# STM32H7x7_CM7 register map
File version: 1.0
CPU: CM7 r0p1, little endian, MPU, FPU, 4 interrupt priority bits
Registers are 32-bit, read-write, reset 0x0 unless marked. A register's access mark holds for its fields unless they carry their own. Offsets are from the block's base; [hi:lo] are bit positions.

## CAN_CCU — CCU registers
Base 0x4000A800
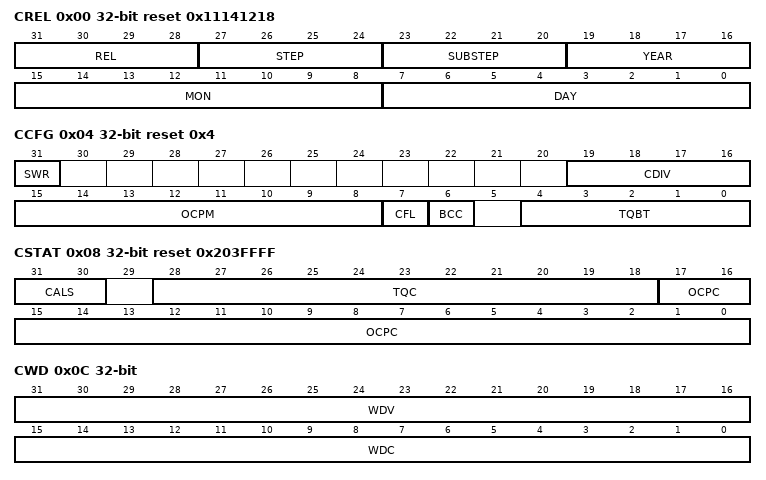
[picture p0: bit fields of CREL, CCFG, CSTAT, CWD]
0x00 CREL ro reset 0x11141218 — Clock Calibration Unit Core Release Register
  [31:28] REL — Core Release
  [27:24] STEP — Step of Core Release
  [23:20] SUBSTEP — Sub-step of Core Release
  [19:16] YEAR — Time Stamp Year
  [15:8] MON — Time Stamp Month
  [7:0] DAY — Time Stamp Day
0x04 CCFG reset 0x4 — Calibration Configuration Register
  [31] SWR — Software Reset
  [19:16] CDIV — Clock Divider
  [15:8] OCPM — Oscillator Clock Periods Minimum
  [7] CFL — Calibration Field Length
  [6] BCC — Bypass Clock Calibration
  [4:0] TQBT — Time Quanta per Bit Time
0x08 CSTAT ro reset 0x203FFFF — Calibration Status Register
  [31:30] CALS — Calibration State
  [28:18] TQC — Time Quanta Counter
  [17:0] OCPC — Oscillator Clock Period Counter
0x0C CWD access per field — Calibration Watchdog Register
  [31:16] WDV ro, [15:0] WDC rw
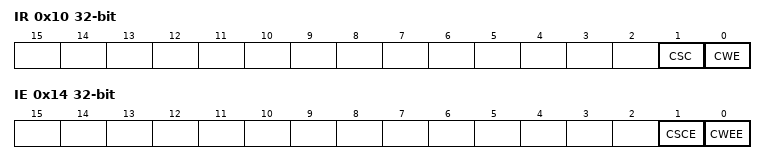
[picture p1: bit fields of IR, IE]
0x10 IR — Clock Calibration Unit Interrupt Register
  [1] CSC — Calibration State Changed
  [0] CWE — Calibration Watchdog Event
0x14 IE — Clock Calibration Unit Interrupt Enable Register
  [1] CSCE — Calibration State Changed Enable
  [0] CWEE — Calibration Watchdog Event Enable

## TIM16 — General-purpose-timers
Base 0x40014400
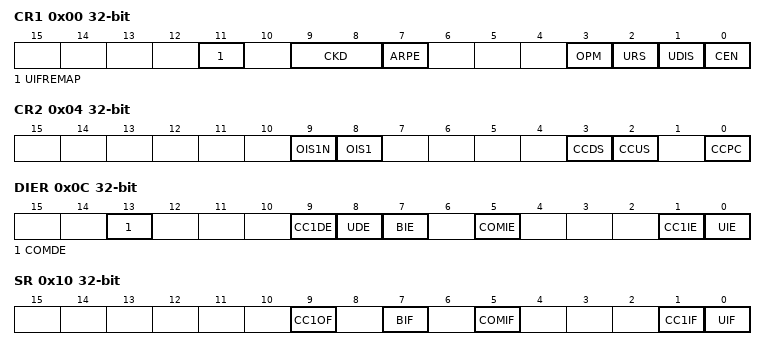
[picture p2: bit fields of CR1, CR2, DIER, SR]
0x00 CR1 — control register 1
  [11] UIFREMAP — UIF status bit remapping
  [9:8] CKD — Clock division
  [7] ARPE — Auto-reload preload enable
  [3] OPM — One-pulse mode
  [2] URS — Update request source
  [1] UDIS — Update disable
  [0] CEN — Counter enable
0x04 CR2 — control register 2
  [9] OIS1N — Output Idle state 1
  [8] OIS1 — Output Idle state 1
  [3] CCDS — Capture/compare DMA selection
  [2] CCUS — Capture/compare control update selection
  [0] CCPC — Capture/compare preloaded control
0x0C DIER — DMA/Interrupt enable register
  [13] COMDE — COM DMA request enable
  [9] CC1DE — Capture/Compare 1 DMA request enable
  [8] UDE — Update DMA request enable
  [7] BIE — Break interrupt enable
  [5] COMIE — COM interrupt enable
  [1] CC1IE — Capture/Compare 1 interrupt enable
  [0] UIE — Update interrupt enable
0x10 SR — status register
  [9] CC1OF — Capture/Compare 1 overcapture flag
  [7] BIF — Break interrupt flag
  [5] COMIF — COM interrupt flag
  [1] CC1IF — Capture/compare 1 interrupt flag
  [0] UIF — Update interrupt flag
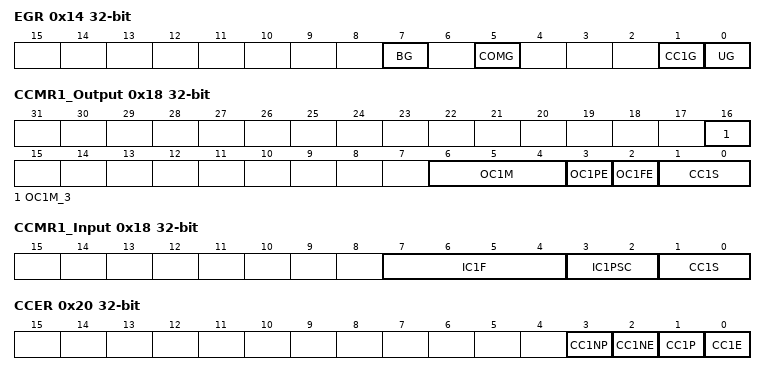
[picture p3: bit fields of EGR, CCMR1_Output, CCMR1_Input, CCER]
0x14 EGR wo — event generation register
  [7] BG — Break generation
  [5] COMG — Capture/Compare control update generation
  [1] CC1G — Capture/compare 1 generation
  [0] UG — Update generation
0x18 CCMR1_Output — capture/compare mode register (output mode)
  [16] OC1M_3 — Output Compare 1 mode
  [6:4] OC1M — Output Compare 1 mode
  [3] OC1PE — Output Compare 1 preload enable
  [2] OC1FE — Output Compare 1 fast enable
  [1:0] CC1S — Capture/Compare 1 selection
0x18 CCMR1_Input (alternate view of CCMR1_Output) — capture/compare mode register 1 (input mode)
  [7:4] IC1F — Input capture 1 filter
  [3:2] IC1PSC — Input capture 1 prescaler
  [1:0] CC1S — Capture/Compare 1 selection
0x20 CCER — capture/compare enable register
  [3] CC1NP — Capture/Compare 1 output Polarity
  [2] CC1NE — Capture/Compare 1 complementary output enable
  [1] CC1P — Capture/Compare 1 output Polarity
  [0] CC1E — Capture/Compare 1 output enable
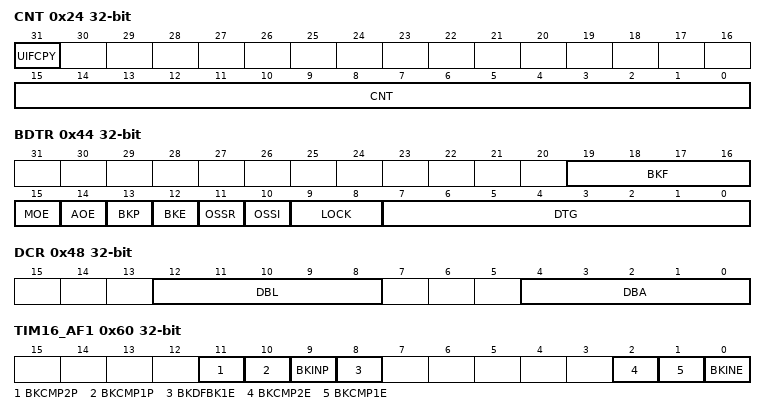
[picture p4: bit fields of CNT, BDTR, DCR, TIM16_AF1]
0x24 CNT access per field — counter
  [31] UIFCPY ro — UIF Copy
  [15:0] CNT rw — counter value
0x28 PSC — prescaler
  [15:0] PSC — Prescaler value
0x2C ARR — auto-reload register
  [15:0] ARR — Auto-reload value
0x30 RCR — repetition counter register
  [7:0] REP — Repetition counter value
0x34 CCR1 — capture/compare register 1
  [15:0] CCR1 — Capture/Compare 1 value
0x44 BDTR — break and dead-time register
  [19:16] BKF — Break filter
  [15] MOE — Main output enable
  [14] AOE — Automatic output enable
  [13] BKP — Break polarity
  [12] BKE — Break enable
  [11] OSSR — Off-state selection for Run mode
  [10] OSSI — Off-state selection for Idle mode
  [9:8] LOCK — Lock configuration
  [7:0] DTG — Dead-time generator setup
0x48 DCR — DMA control register
  [12:8] DBL — DMA burst length
  [4:0] DBA — DMA base address
0x4C DMAR — DMA address for full transfer
  [15:0] DMAB — DMA register for burst accesses
0x60 TIM16_AF1 — TIM16 alternate function register 1
  [11] BKCMP2P — BRK COMP2 input polarity
  [10] BKCMP1P — BRK COMP1 input polarity
  [9] BKINP — BRK BKIN input polarity
  [8] BKDFBK1E — BRK dfsdm1_break[1] enable
  [2] BKCMP2E — BRK COMP2 enable
  [1] BKCMP1E — BRK COMP1 enable
  [0] BKINE — BRK BKIN input enable
0x68 TIM16_TISEL — TIM16 input selection register
  [3:0] TI1SEL — selects TI1[0] to TI1[15] input

## TIM17 — General-purpose-timers
Base 0x40014800
Registers as TIM16 (with TIM16 read as TIM17).
